VERSION ""

NS_ :

BS_:

BU_: Device Host
VAL_TABLE_ ON_OFF_ERR_NA 3 "NA" 2 "ERROR" 1 "OFF" 0 "ON" ;

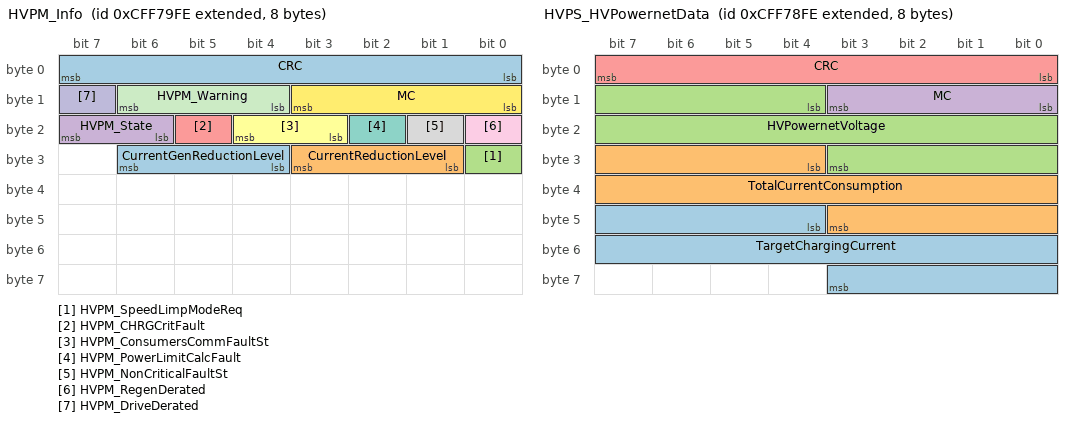
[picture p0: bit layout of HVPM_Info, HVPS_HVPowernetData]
BO_ 2365553150 HVPM_Info: 8 Vector__XXX
 SG_ CurrentGenReductionLevel : 28|3@1+ (1,0) [0|7] "" Vector__XXX
 SG_ CurrentReductionLevel : 25|3@1+ (1,0) [0|7] "" Vector__XXX
 SG_ HVPM_SpeedLimpModeReq : 24|1@1+ (1,0) [0|3] "" Vector__XXX
 SG_ HVPM_State : 22|2@1+ (1,0) [0|3] "" Vector__XXX
 SG_ HVPM_CHRGCritFault : 21|1@1+ (1,0) [0|1] "" Vector__XXX
 SG_ HVPM_ConsumersCommFaultSt : 19|2@1+ (1,0) [0|1] "" Vector__XXX
 SG_ HVPM_PowerLimitCalcFault : 18|1@1+ (1,0) [0|1] "" Vector__XXX
 SG_ HVPM_NonCriticalFaultSt : 17|1@1+ (1,0) [0|1] "" Vector__XXX
 SG_ HVPM_RegenDerated : 16|1@1+ (1,0) [0|1] "" Vector__XXX
 SG_ HVPM_DriveDerated : 15|1@1+ (1,0) [0|1] "" Vector__XXX
 SG_ HVPM_Warning : 12|3@1+ (1,0) [0|7] "" Vector__XXX
 SG_ MC : 8|4@1+ (1,0) [0|0] "" Vector__XXX
 SG_ CRC : 0|8@1+ (1,0) [0|0] "" Vector__XXX

BO_ 2365552894 HVPS_HVPowernetData: 8 Vector__XXX
 SG_ TargetChargingCurrent : 44|16@1+ (0.1,-3276.8) [-3276.8|3276.7] "A" Vector__XXX
 SG_ TotalCurrentConsumption : 28|16@1+ (0.1,-3276.8) [-3276.8|3276.7] "A" Vector__XXX
 SG_ HVPowernetVoltage : 12|16@1+ (0.05,0) [0|3276.75] "V" Vector__XXX
 SG_ MC : 8|4@1+ (1,0) [0|0] "" Vector__XXX
 SG_ CRC : 0|8@1+ (1,0) [0|0] "" Vector__XXX

BO_ 2364663038 HVPS_HVILStatus: 8 Vector__XXX
 SG_ CHRG_HVIL : 60|2@1+ (1,0) [0|3] "" Vector__XXX
 SG_ OBC2_HVIL : 58|2@1+ (1,0) [0|3] "" Vector__XXX
 SG_ OBC1_HVIL : 56|2@1+ (1,0) [0|3] "" Vector__XXX
 SG_ DCDC3_HVIL : 54|2@1+ (1,0) [0|3] "" Vector__XXX
 SG_ DCDC2_HVIL : 52|2@1+ (1,0) [0|3] "" Vector__XXX
 SG_ DCDC1_HVIL : 50|2@1+ (1,0) [0|3] "" Vector__XXX
 SG_ IDU2_HVIL : 48|2@1+ (1,0) [0|3] "" Vector__XXX
 SG_ IDU1_HVIL : 46|2@1+ (1,0) [0|3] "" Vector__XXX
 SG_ AuxInv_HVIL : 44|2@1+ (1,0) [0|3] "" Vector__XXX
 SG_ ACPWT4_HVIL : 42|2@1+ (1,0) [0|3] "" Vector__XXX
 SG_ ACPWT3_HVIL : 40|2@1+ (1,0) [0|3] "" Vector__XXX
 SG_ ACPWT2_HVIL : 38|2@1+ (1,0) [0|3] "" Vector__XXX
 SG_ ACPWT1_HVIL : 36|2@1+ (1,0) [0|3] "" Vector__XXX
 SG_ HVH_HVIL : 34|2@1+ (1,0) [0|3] "" Vector__XXX
 SG_ ACComp4_HVIL : 32|2@1+ (1,0) [0|3] "" Vector__XXX
 SG_ ACComp3_HVIL : 30|2@1+ (1,0) [0|3] "" Vector__XXX
 SG_ ACComp2_HVIL : 28|2@1+ (1,0) [0|3] "" Vector__XXX
 SG_ ACComp1_HVIL : 26|2@1+ (1,0) [0|3] "" Vector__XXX
 SG_ PTC5_HVIL : 24|2@1+ (1,0) [0|3] "" Vector__XXX
 SG_ PTC4_HVIL : 22|2@1+ (1,0) [0|3] "" Vector__XXX
 SG_ PTC3_HVIL : 20|2@1+ (1,0) [0|3] "" Vector__XXX
 SG_ PTC2_HVIL : 18|2@1+ (1,0) [0|3] "" Vector__XXX
 SG_ PTC1_HVIL : 16|2@1+ (1,0) [0|3] "" Vector__XXX
 SG_ BatteryPack_HVIL : 14|2@1+ (1,0) [0|3] "" Vector__XXX
 SG_ EDS_HVIL : 12|2@1+ (1,0) [0|3] "" Vector__XXX
 SG_ MC : 8|4@1+ (1,0) [0|0] "" Vector__XXX
 SG_ CRC : 0|8@1+ (1,0) [0|0] "" Vector__XXX

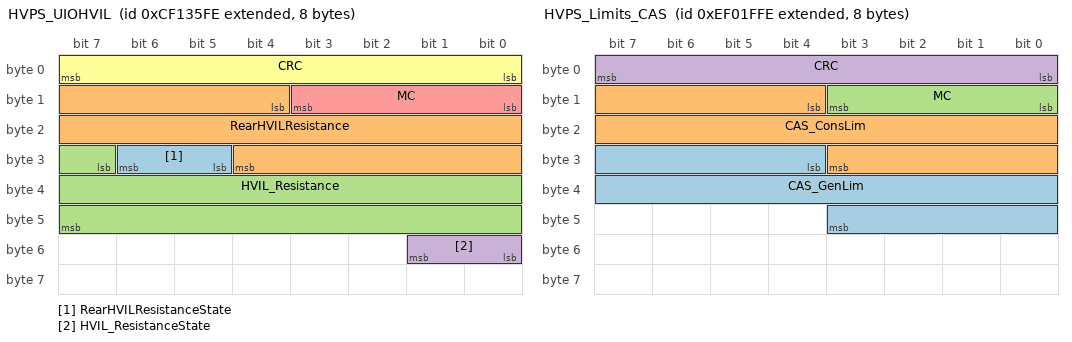
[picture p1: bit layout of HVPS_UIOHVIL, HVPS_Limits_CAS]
BO_ 2364618238 HVPS_UIOHVIL: 8 Vector__XXX
 SG_ RearHVILResistanceState : 29|2@1+ (1,0) [0|3] "" Vector__XXX
 SG_ RearHVILResistance : 12|17@1+ (0.1,0) [0|10000] "Ohm" Vector__XXX
 SG_ HVIL_Resistance : 31|17@1+ (0.1,0) [0|10000] "Ohm" Vector__XXX
 SG_ HVIL_ResistanceState : 48|2@1+ (1,0) [0|0] "" Vector__XXX
 SG_ MC : 8|4@1+ (1,0) [0|0] "" Vector__XXX
 SG_ CRC : 0|8@1+ (1,0) [0|0] "" Vector__XXX

BO_ 2398101502 HVPS_Limits_CAS: 8 Vector__XXX
 SG_ CAS_GenLim : 28|16@1+ (0.1,0) [0|6553.5] "kW" Vector__XXX
 SG_ CAS_ConsLim : 12|16@1+ (0.1,0) [0|6553.5] "kW" Vector__XXX
 SG_ MC : 8|4@1+ (1,0) [0|0] "" Vector__XXX
 SG_ CRC : 0|8@1+ (1,0) [0|0] "" Vector__XXX

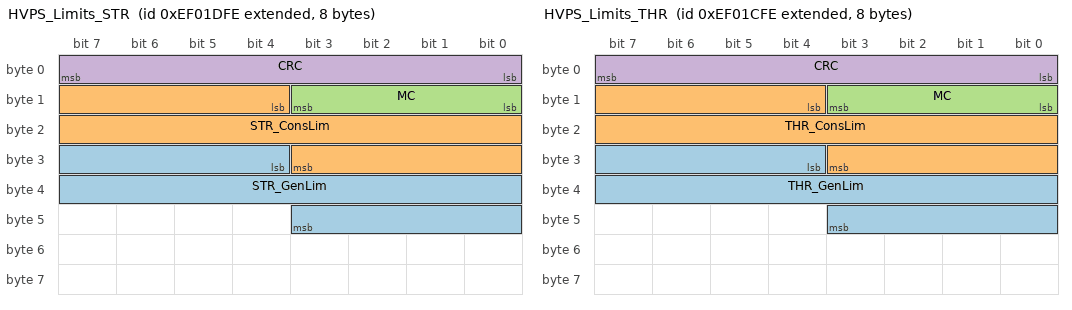
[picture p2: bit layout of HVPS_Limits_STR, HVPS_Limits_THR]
BO_ 2398100990 HVPS_Limits_STR: 8 Vector__XXX
 SG_ STR_GenLim : 28|16@1+ (0.1,0) [0|6553.5] "kW" Vector__XXX
 SG_ STR_ConsLim : 12|16@1+ (0.1,0) [0|6553.5] "kW" Vector__XXX
 SG_ MC : 8|4@1+ (1,0) [0|0] "" Vector__XXX
 SG_ CRC : 0|8@1+ (1,0) [0|0] "" Vector__XXX

BO_ 2398100734 HVPS_Limits_THR: 8 Vector__XXX
 SG_ THR_GenLim : 28|16@1+ (0.1,0) [0|6553.5] "kW" Vector__XXX
 SG_ THR_ConsLim : 12|16@1+ (0.1,0) [0|6553.5] "kW" Vector__XXX
 SG_ MC : 8|4@1+ (1,0) [0|0] "" Vector__XXX
 SG_ CRC : 0|8@1+ (1,0) [0|0] "" Vector__XXX

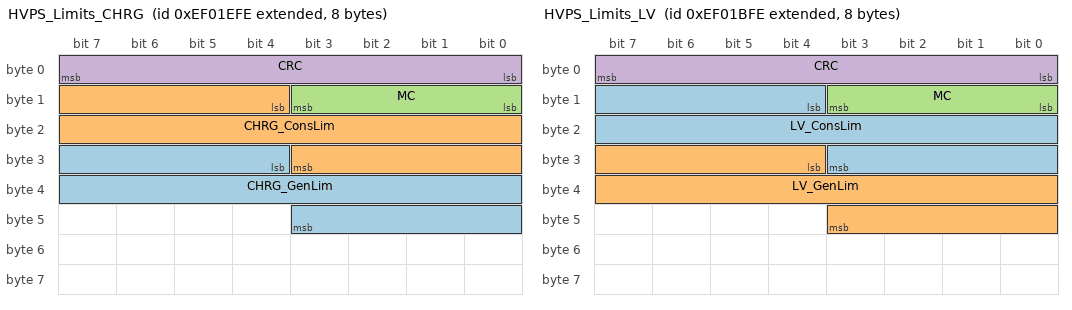
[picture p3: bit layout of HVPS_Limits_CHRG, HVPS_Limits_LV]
BO_ 2398101246 HVPS_Limits_CHRG: 8 Vector__XXX
 SG_ CHRG_GenLim : 28|16@1+ (0.1,0) [0|6553.5] "kW" Vector__XXX
 SG_ CHRG_ConsLim : 12|16@1+ (0.1,0) [0|6553.5] "kW" Vector__XXX
 SG_ MC : 8|4@1+ (1,0) [0|0] "" Vector__XXX
 SG_ CRC : 0|8@1+ (1,0) [0|0] "" Vector__XXX

BO_ 2398100478 HVPS_Limits_LV: 8 Vector__XXX
 SG_ LV_ConsLim : 12|16@1+ (0.1,0) [0|6553.5] "kW" Vector__XXX
 SG_ LV_GenLim : 28|16@1+ (0.1,0) [0|6553.5] "kW" Vector__XXX
 SG_ MC : 8|4@1+ (1,0) [0|0] "" Vector__XXX
 SG_ CRC : 0|8@1+ (1,0) [0|0] "" Vector__XXX

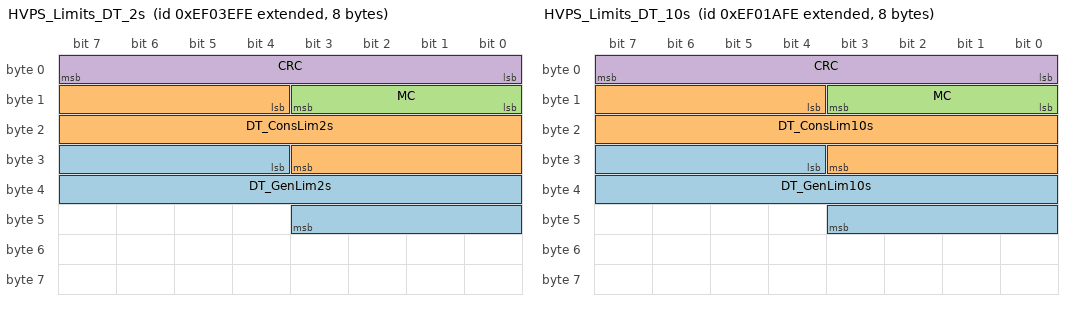
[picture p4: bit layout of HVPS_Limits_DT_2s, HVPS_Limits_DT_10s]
BO_ 2398109438 HVPS_Limits_DT_2s: 8 Vector__XXX
 SG_ DT_GenLim2s : 28|16@1+ (0.1,0) [0|6553.5] "kW" Vector__XXX
 SG_ DT_ConsLim2s : 12|16@1+ (0.1,0) [0|6553.5] "kW" Vector__XXX
 SG_ MC : 8|4@1+ (1,0) [0|0] "" Vector__XXX
 SG_ CRC : 0|8@1+ (1,0) [0|0] "" Vector__XXX

BO_ 2398100222 HVPS_Limits_DT_10s: 8 Vector__XXX
 SG_ DT_GenLim10s : 28|16@1+ (0.1,0) [0|6553.5] "kW" Vector__XXX
 SG_ DT_ConsLim10s : 12|16@1+ (0.1,0) [0|6553.5] "kW" Vector__XXX
 SG_ MC : 8|4@1+ (1,0) [0|0] "" Vector__XXX
 SG_ CRC : 0|8@1+ (1,0) [0|0] "" Vector__XXX

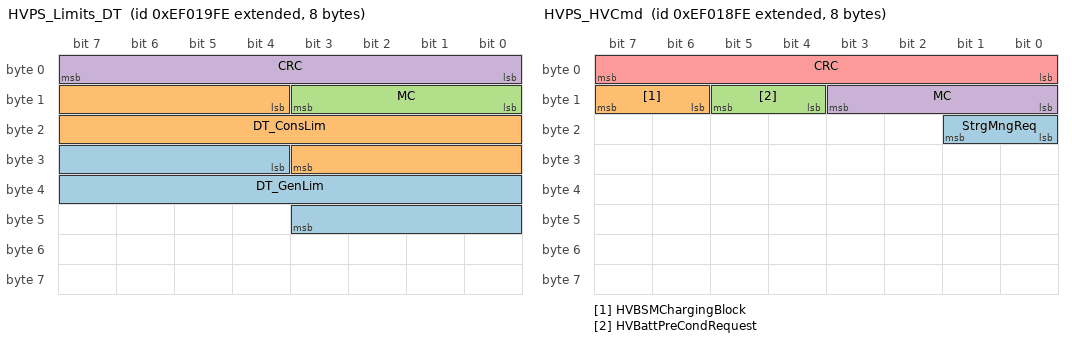
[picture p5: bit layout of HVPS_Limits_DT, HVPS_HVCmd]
BO_ 2398099966 HVPS_Limits_DT: 8 Vector__XXX
 SG_ DT_GenLim : 28|16@1+ (0.1,0) [0|6553.5] "kW" Vector__XXX
 SG_ DT_ConsLim : 12|16@1+ (0.1,0) [0|6553.5] "kW" Vector__XXX
 SG_ MC : 8|4@1+ (1,0) [0|0] "" Vector__XXX
 SG_ CRC : 0|8@1+ (1,0) [0|0] "" Vector__XXX

BO_ 2398099710 HVPS_HVCmd: 8 Vector__XXX
 SG_ StrgMngReq : 16|2@1+ (1,0) [0|3] "" Vector__XXX
 SG_ HVBSMChargingBlock : 14|2@1+ (1,0) [0|3] "" Vector__XXX
 SG_ HVBattPreCondRequest : 12|2@1+ (1,0) [0|3] "" Vector__XXX
 SG_ MC : 8|4@1+ (1,0) [0|0] "" Vector__XXX
 SG_ CRC : 0|8@1+ (1,0) [0|0] "" Vector__XXX

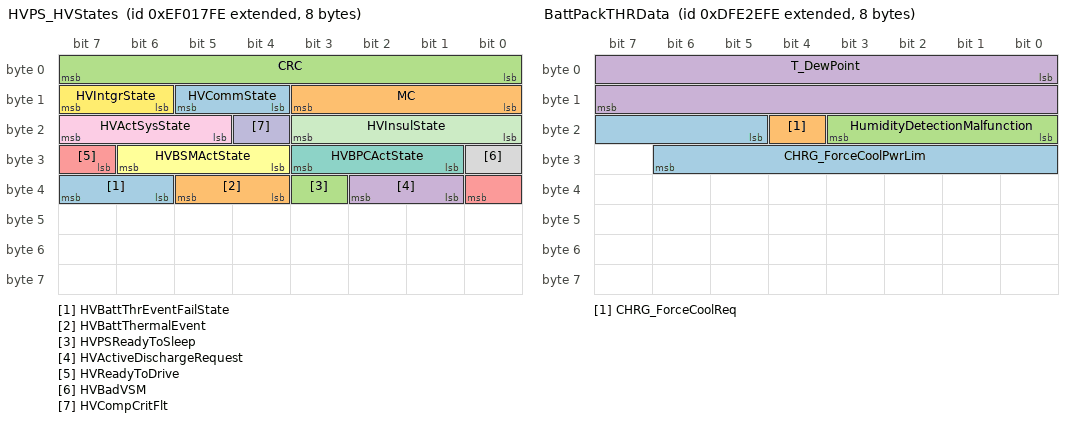
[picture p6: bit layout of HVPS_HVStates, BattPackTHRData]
BO_ 2398099454 HVPS_HVStates: 8 Vector__XXX
 SG_ HVBattThrEventFailState : 38|2@1+ (1,0) [0|3] "" Vector__XXX
 SG_ HVBattThermalEvent : 36|2@1+ (1,0) [0|3] "" Vector__XXX
 SG_ HVPSReadyToSleep : 35|1@1+ (1,0) [0|1] "" Vector__XXX
 SG_ HVActiveDischargeRequest : 33|2@1+ (1,0) [0|3] "" Vector__XXX
 SG_ HVReadyToDrive : 31|2@1+ (1,0) [0|3] "" Vector__XXX
 SG_ HVBSMActState : 28|3@1+ (1,0) [0|7] "" Vector__XXX
 SG_ HVBPCActState : 25|3@1+ (1,0) [0|7] "" Vector__XXX
 SG_ HVBadVSM : 24|1@1+ (1,0) [0|1] "" Vector__XXX
 SG_ HVActSysState : 21|3@1+ (1,0) [0|7] "" Vector__XXX
 SG_ HVCompCritFlt : 20|1@1+ (1,0) [0|1] "" Vector__XXX
 SG_ HVInsulState : 16|4@1+ (1,0) [0|15] "" Vector__XXX
 SG_ HVIntgrState : 14|2@1+ (1,0) [0|3] "" Vector__XXX
 SG_ HVCommState : 12|2@1+ (1,0) [0|3] "" Vector__XXX
 SG_ MC : 8|4@1+ (1,0) [0|0] "" Vector__XXX
 SG_ CRC : 0|8@1+ (1,0) [0|0] "" Vector__XXX

BO_ 2382245630 BattPackTHRData: 8 Vector__XXX
 SG_ CHRG_ForceCoolPwrLim : 21|10@1+ (0.1,0) [0|102.3] "kW" Vector__XXX
 SG_ CHRG_ForceCoolReq : 20|1@1+ (1,0) [0|0] "" Vector__XXX
 SG_ HumidityDetectionMalfunction : 16|4@1+ (1,0) [0|0] "" Vector__XXX
 SG_ T_DewPoint : 0|16@1+ (0.03125,-273) [-273|1774.96875] "degC" Vector__XXX

CM_ "$File: //depot/auto/dbc/Software_Modules/HV_System/HVPS/0.7.2.0/HVPS.dbc $
$Change: 215800 $
$DateTime: 2024/08/14 11:28:58 $
$Revision: #1 $";
CM_ SG_ 2398099454 HVBPCActState "Actual state of HV battery pre-conditioning procedure";
BA_DEF_  "BusType" STRING ;
BA_DEF_  "DBName" STRING ;
BA_DEF_  "DatabaseVersion" STRING ;
BA_DEF_ BO_  "GenMsgCycleTime" INT 0 3600000;
BA_DEF_ BO_  "GenMsgILSupport" ENUM  "No","Yes";
BA_DEF_ BO_  "GenMsgRequestable" INT 0 1;
BA_DEF_ BO_  "GenMsgSendType" ENUM  "cyclic","NotUsed","NotUsed","NotUsed","NotUsed","NotUsed","NotUsed","IfActive","noMsgSendType";
BA_DEF_ SG_  "GenSigEVName" STRING ;
BA_DEF_ SG_  "GenSigILSupport" ENUM  "No","Yes";
BA_DEF_ SG_  "GenSigSendType" ENUM  "Cyclic","OnWrite","OnWriteWithRepetition","OnChange","OnChangeWithRepetition","IfActive","IfActiveWithRepetition","NoSigSendType";
BA_DEF_ SG_  "GenSigStartValue" INT 0 2147483647;
BA_DEF_ BU_  "NmStationAddress" INT 0 255;
BA_DEF_  "ProtocolType" STRING ;
BA_DEF_  "SAE_J1939_21_SpecVersion" STRING ;
BA_DEF_  "SAE_J1939_71_SpecVersion" STRING ;
BA_DEF_  "SAE_J1939_73_SpecVersion" STRING ;
BA_DEF_  "SAE_J1939_75_SpecVersion" STRING ;
BA_DEF_  "SAE_J1939_81_SpecVersion" STRING ;
BA_DEF_  "SAE_J1939_DA_SpecVersion" STRING ;
BA_DEF_ BO_  "SendOnChange" ENUM  "No","Yes";
BA_DEF_ SG_  "SigType" ENUM  "Default","Range","RangeSigned","ASCII","Discrete","Control","ReferencePGN","DTC","StringDelimiter","StringLength","StringLengthControl","MessageCounter","MessageChecksum";
BA_DEF_ BO_  "VFrameFormat" ENUM  "StandardCAN","ExtendedCAN","reserved","J1939PG","reserved","reserved","reserved","reserved","reserved","reserved","reserved","reserved","reserved","reserved","StandardCAN_FD","ExtendedCAN_FD";
BA_DEF_ BO_  "Producer" STRING ;
BA_DEF_DEF_  "BusType" "";
BA_DEF_DEF_  "DBName" "";
BA_DEF_DEF_  "DatabaseVersion" "";
BA_DEF_DEF_  "GenMsgCycleTime" 0;
BA_DEF_DEF_  "GenMsgILSupport" "Yes";
BA_DEF_DEF_  "GenMsgRequestable" 1;
BA_DEF_DEF_  "GenMsgSendType" "noMsgSendType";
BA_DEF_DEF_  "GenSigEVName" "Env@Nodename_@Signame";
BA_DEF_DEF_  "GenSigILSupport" "Yes";
BA_DEF_DEF_  "GenSigSendType" "NoSigSendType";
BA_DEF_DEF_  "GenSigStartValue" 0;
BA_DEF_DEF_  "NmStationAddress" 254;
BA_DEF_DEF_  "ProtocolType" "";
BA_DEF_DEF_  "SAE_J1939_21_SpecVersion" "";
BA_DEF_DEF_  "SAE_J1939_71_SpecVersion" "";
BA_DEF_DEF_  "SAE_J1939_73_SpecVersion" "";
BA_DEF_DEF_  "SAE_J1939_75_SpecVersion" "";
BA_DEF_DEF_  "SAE_J1939_81_SpecVersion" "";
BA_DEF_DEF_  "SAE_J1939_DA_SpecVersion" "";
BA_DEF_DEF_  "SendOnChange" "No";
BA_DEF_DEF_  "Producer" "HVPS";
BA_DEF_DEF_  "SigType" "Default";
BA_DEF_DEF_  "VFrameFormat" "J1939PG";
BA_ "BusType" "CAN";
BA_ "DatabaseVersion" "1.0";
BA_ "ProtocolType" "J1939";
BA_ "SAE_J1939_21_SpecVersion" "2006-10";
BA_ "SAE_J1939_71_SpecVersion" "2012-10";
BA_ "SAE_J1939_73_SpecVersion" "2012-10";
BA_ "SAE_J1939_75_SpecVersion" "2012-05";
BA_ "SAE_J1939_81_SpecVersion" "2012-05";
BA_ "SAE_J1939_DA_SpecVersion" "2015-01";
BA_ "DBName" "HVPS";
BA_ "GenMsgSendType" BO_ 2365553150 0;
BA_ "GenMsgCycleTime" BO_ 2365553150 100;
BA_ "GenMsgSendType" BO_ 2365552894 0;
BA_ "GenMsgCycleTime" BO_ 2365552894 100;
BA_ "SendOnChange" BO_ 2364663038 1;
BA_ "GenMsgSendType" BO_ 2364663038 0;
BA_ "GenMsgCycleTime" BO_ 2364663038 100;
BA_ "GenMsgSendType" BO_ 2364618238 0;
BA_ "GenMsgCycleTime" BO_ 2364618238 100;
BA_ "GenMsgCycleTime" BO_ 2398101502 1000;
BA_ "GenMsgSendType" BO_ 2398101502 0;
BA_ "GenMsgCycleTime" BO_ 2398100990 1000;
BA_ "GenMsgSendType" BO_ 2398100990 0;
BA_ "GenMsgCycleTime" BO_ 2398100734 1000;
BA_ "GenMsgSendType" BO_ 2398100734 0;
BA_ "GenMsgCycleTime" BO_ 2398101246 1000;
BA_ "GenMsgSendType" BO_ 2398101246 0;
BA_ "GenMsgCycleTime" BO_ 2398100478 1000;
BA_ "GenMsgSendType" BO_ 2398100478 0;
BA_ "GenMsgCycleTime" BO_ 2398109438 100;
BA_ "GenMsgSendType" BO_ 2398109438 0;
BA_ "GenMsgCycleTime" BO_ 2398100222 100;
BA_ "GenMsgSendType" BO_ 2398100222 0;
BA_ "GenMsgCycleTime" BO_ 2398099966 1000;
BA_ "GenMsgSendType" BO_ 2398099966 0;
BA_ "GenMsgCycleTime" BO_ 2398099710 100;
BA_ "GenMsgSendType" BO_ 2398099710 0;
BA_ "SendOnChange" BO_ 2398099710 1;
BA_ "GenMsgSendType" BO_ 2398099454 0;
BA_ "GenMsgCycleTime" BO_ 2398099454 100;
BA_ "SendOnChange" BO_ 2398099454 1;
BA_ "GenMsgSendType" BO_ 2382245630 0;
BA_ "GenMsgCycleTime" BO_ 2382245630 1000;
BA_ "GenSigStartValue" SG_ 2365553150 HVPM_State 3;
BA_ "GenSigStartValue" SG_ 2365553150 HVPM_ConsumersCommFaultSt 3;
BA_ "GenSigStartValue" SG_ 2365553150 HVPM_Warning 7;
BA_ "GenSigStartValue" SG_ 2365552894 TargetChargingCurrent 32768;
BA_ "GenSigStartValue" SG_ 2365552894 TotalCurrentConsumption 32768;
BA_ "GenSigSendType" SG_ 2364618238 HVIL_ResistanceState 0;
BA_ "SigType" SG_ 2364618238 HVIL_ResistanceState 4;
BA_ "GenSigStartValue" SG_ 2398099454 HVReadyToDrive 3;
VAL_ 2365553150 HVPM_State 3 "NotAvailable" 2 "LimpHomeMode" 1 "ReducedPowerMode" 0 "NormalMode" ;
VAL_ 2365553150 HVPM_ConsumersCommFaultSt 3 "NotAvailable" 2 "Fault" 1 "Warning" 0 "NoFault" ;
VAL_ 2365553150 HVPM_Warning 7 "NotAvailable" 3 "Warning" 2 "HVPNOverload" 1 "CriticalHVPNfault" 0 "No warning" ;
VAL_ 2364663038 CHRG_HVIL 3 "SNA" 2 "FAULT" 1 "OK" 0 "Initializing" ;
VAL_ 2364663038 OBC2_HVIL 3 "SNA" 2 "FAULT" 1 "OK" 0 "Initializing" ;
VAL_ 2364663038 OBC1_HVIL 3 "SNA" 2 "FAULT" 1 "OK" 0 "Initializing" ;
VAL_ 2364663038 DCDC3_HVIL 3 "SNA" 2 "FAULT" 1 "OK" 0 "Initializing" ;
VAL_ 2364663038 DCDC2_HVIL 3 "SNA" 2 "FAULT" 1 "OK" 0 "Initializing" ;
VAL_ 2364663038 DCDC1_HVIL 3 "SNA" 2 "FAULT" 1 "OK" 0 "Initializing" ;
VAL_ 2364663038 IDU2_HVIL 3 "SNA" 2 "FAULT" 1 "OK" 0 "Initializing" ;
VAL_ 2364663038 IDU1_HVIL 3 "SNA" 2 "FAULT" 1 "OK" 0 "Initializing" ;
VAL_ 2364663038 AuxInv_HVIL 3 "SNA" 2 "FAULT" 1 "OK" 0 "Initializing" ;
VAL_ 2364663038 ACPWT4_HVIL 3 "SNA" 2 "FAULT" 1 "OK" 0 "Initializing" ;
VAL_ 2364663038 ACPWT3_HVIL 3 "SNA" 2 "FAULT" 1 "OK" 0 "Initializing" ;
VAL_ 2364663038 ACPWT2_HVIL 3 "SNA" 2 "FAULT" 1 "OK" 0 "Initializing" ;
VAL_ 2364663038 ACPWT1_HVIL 3 "SNA" 2 "FAULT" 1 "OK" 0 "Initializing" ;
VAL_ 2364663038 HVH_HVIL 3 "SNA" 2 "FAULT" 1 "OK" 0 "Initializing" ;
VAL_ 2364663038 ACComp4_HVIL 3 "SNA" 2 "FAULT" 1 "OK" 0 "Initializing" ;
VAL_ 2364663038 ACComp3_HVIL 3 "SNA" 2 "FAULT" 1 "OK" 0 "Initializing" ;
VAL_ 2364663038 ACComp2_HVIL 3 "SNA" 2 "FAULT" 1 "OK" 0 "Initializing" ;
VAL_ 2364663038 ACComp1_HVIL 3 "SNA" 2 "FAULT" 1 "OK" 0 "Initializing" ;
VAL_ 2364663038 PTC5_HVIL 3 "SNA" 2 "FAULT" 1 "OK" 0 "Initializing" ;
VAL_ 2364663038 PTC4_HVIL 3 "SNA" 2 "FAULT" 1 "OK" 0 "Initializing" ;
VAL_ 2364663038 PTC3_HVIL 3 "SNA" 2 "FAULT" 1 "OK" 0 "Initializing" ;
VAL_ 2364663038 PTC2_HVIL 3 "SNA" 2 "FAULT" 1 "OK" 0 "Initializing" ;
VAL_ 2364663038 PTC1_HVIL 3 "SNA" 2 "FAULT" 1 "OK" 0 "Initializing" ;
VAL_ 2364663038 BatteryPack_HVIL 3 "SNA" 2 "FAULT" 1 "OK" 0 "Initializing" ;
VAL_ 2364663038 EDS_HVIL 3 "SNA" 2 "FAULT" 1 "OK" 0 "Initializing" ;
VAL_ 2364618238 RearHVILResistanceState 3 "SNA" 0 "Initializing" 1 "Operation" 2 "OpenCircuit" ;
VAL_ 2364618238 HVIL_ResistanceState 0 "Initializing" 1 "Operation" 2 "OpenCircuit" 3 "SNA" ;
VAL_ 2398099710 StrgMngReq 3 "Fault" 2 "Reserved" 1 "True" 0 "False" ;
VAL_ 2398099710 HVBSMChargingBlock 3 "HVBSMCB_NotAvailable" 2 "HVBSMCB_Error" 1 "HVBSMCB_Off" 0 "HVBSMCB_On" ;
VAL_ 2398099710 HVBattPreCondRequest 0 "HVBPCR_On" 1 "HVBPCR_Off" 2 "HVBPCR_Error" 3 "HVBPCR_NotAvailable" ;
VAL_ 2398099454 HVBattThrEventFailState 3 "NA" 2 "Reserved" 1 "Warning" 0 "NoFault" ;
VAL_ 2398099454 HVBattThermalEvent 3 "NA" 2 "Detected" 1 "High_Risk" 0 "Not_Detected" ;
VAL_ 2398099454 HVActiveDischargeRequest 3 "TakeNoAction" 2 "Reserved" 1 "On" 0 "Off" ;
VAL_ 2398099454 HVReadyToDrive 3 "NA" 2 "Error" 1 "Ready" 0 "Not Ready" ;
VAL_ 2398099454 HVBSMActState 7 "HVBSM_NotAvailable" 6 "HVBSM_Error" 5 "HVBSM_Reserved2" 4 "HVBSM_Reserved1" 3 "HVBSM_Fault" 2 "HVBSM_Complete" 1 "HVBSM_InProcess" 0 "HVBSM_Default" ;
VAL_ 2398099454 HVBPCActState 0 "HVBPC_Default" 1 "HVBPC_InProcess" 2 "HVBPC_Complete" 3 "HVBPC_Fault" 4 "HVBPC_Blocked" 5 "HVBPC_Reserved2" 6 "HVBPC_Error" 7 "HVBPC_NotAvailable" ;
VAL_ 2398099454 HVActSysState 0 "HVState_Initializing" 1 "HVState_Off" 2 "HVState_Active" 3 "HVState_Activating" 4 "HVState_ShuttingDown" 5 "HVState_Discharging" 6 "HVState_Fault" 7 "HVState_Service" ;
VAL_ 2398099454 HVInsulState 0 "HVInsul_Init" 1 "HVInsul_Ok" 2 "HVInsul_Warn" 3 "HVInsul_Crit" ;
VAL_ 2398099454 HVIntgrState 0 "HVIntgr_Init" 1 "HVIntgr_Ok" 2 "HVIntgr_Fault" 3 "HVIntgr_NA" ;
VAL_ 2398099454 HVCommState 0 "HVComm_Init" 1 "HVComm_Ok" 2 "HVComm_Fault" 3 "HVComm_NA" ;
VAL_ 2382245630 HumidityDetectionMalfunction 3 "HumMD_NA" 2 "HumMD_Fault" 1 "HumMD_Warning" 0 "HumMD_No_Fault" ;
